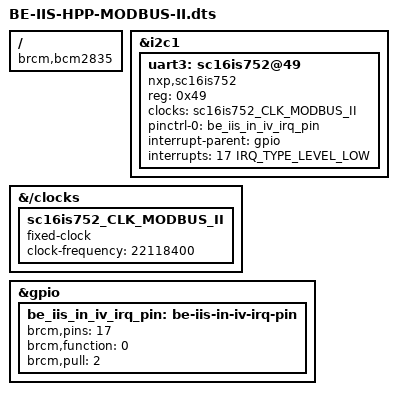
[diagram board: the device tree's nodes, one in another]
// Raspberry Pi DT overlay: Microchip SC16IS752 on I2C1
// IRQ: BCM GPIO17
// 7-bit I2C address: 0x49
// 8-bit write address: 0x92
//
// Supported Raspberry Pi models (SPI0-based):
//   - Raspberry Pi Zero / Zero W / Zero 2 W
//   - Raspberry Pi 1 (A/B/B+)
//   - Raspberry Pi 2 (v1.1 / v1.2)
//   - Raspberry Pi 3 (3A+, 3B, 3B+)
//   - Raspberry Pi 4 (4B, 400, CM4)
//   - Raspberry Pi 5
//
// Notes:
//   - Uses I2C1
//   - Uses BCM GPIO numbering
//   - Works across bcm2835 / bcm2711 / bcm2712
//   - INT_N is usually active low, therefore LEVEL_LOW is used here

/dts-v1/;
/plugin/;

#include <dt-bindings/interrupt-controller/irq.h>

/ {
	compatible = "brcm,bcm2835", "brcm,bcm2711", "brcm,bcm2712";

	fragment@1 {
		target = <&i2c1>;
		__overlay__ {
			#address-cells = <1>;
			#size-cells = <0>;
			status = "okay";

			uart3: sc16is752@49 {
				compatible = "nxp,sc16is752";
				reg = <0x49>;

				clocks = <&sc16is752_CLK_MODBUS_II>;

				/* Required for stable IRQ handling on Raspberry Pi 5 / RP1 */
                                pinctrl-names = "default";
                                pinctrl-0 = <&be_iis_in_iv_irq_pin>;
                                
				interrupt-parent = <&gpio>;
				interrupts = <17 IRQ_TYPE_LEVEL_LOW>;

				status = "okay";
			};
		};
	};

	fragment@30 {
		target-path = "/clocks";
		__overlay__ {
			sc16is752_CLK_MODBUS_II: sc16is752_CLK_MODBUS_II {
				compatible = "fixed-clock";
				#clock-cells = <0>;
				clock-frequency = <22118400>;
			};
		};
	};

	/* GPIO17 as input, pull-up (IRQ pin) */
	fragment@2 {
	    target = <&gpio>;
	    __overlay__ {
		be_iis_in_iv_irq_pin: be-iis-in-iv-irq-pin {
		    brcm,pins = <17>;
		    brcm,function = <0>;
		    brcm,pull = <2>;
		};
	    };
	};

	__overrides__ {
		int_pin = <&uart3>, "interrupts:0";
	};
};

/*
 * Brechel Electronic
 * Industrial Interface Systems
 *
 * Product: BE-IIS-HPP-CAN-FD-SIC
 *
 * Website:
 * https://www.be-iis.eu
 *
 * Digi-Key:
 * https://www.digikey.de/en/products/detail/brechel-electronic-industrial-interface-systems-be-iis/BE-IIS-HPP-MODBUS/29436900
 */
